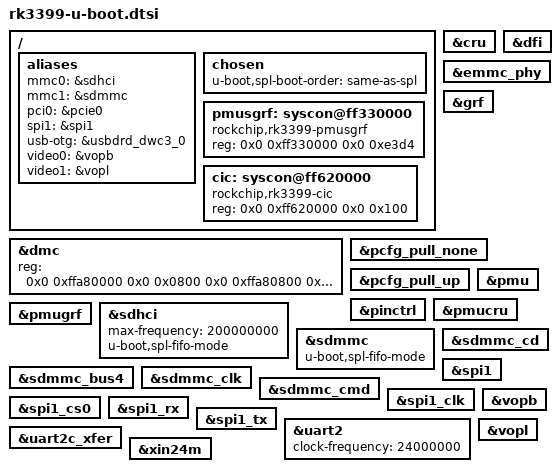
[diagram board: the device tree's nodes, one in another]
// SPDX-License-Identifier: GPL-2.0+
/*
 * Copyright (C) 2019 Jagan Teki <jagan@amarulasolutions.com>
 */
#include "rockchip-u-boot.dtsi"

/ {
	aliases {
		mmc0 = &sdhci;
		mmc1 = &sdmmc;
		pci0 = &pcie0;
		spi1 = &spi1;
		/* the OTG port env usb_otg sets the role of (boot/usb_otg_role.c) */
		usb-otg = &usbdrd_dwc3_0;

		/*
		 * VOPB is video0, VOPL is video1 -- and without these the order
		 * is the reverse, by accident.
		 *
		 * UCLASS_VIDEO carries DM_UC_FLAG_SEQ_ALIAS, so with no videoN
		 * alias the sequence numbers fall out of bind order, which is
		 * device tree node order, and rk3399-base.dtsi happens to list
		 * vop@ff8f0000 (VOPL, 2560x1600) before vop@ff900000 (VOPB,
		 * 4096x2160). That made the small VOP video0.
		 *
		 * It matters because of what probes at boot. With the console
		 * in the environment -- CONFIG_SYS_CONSOLE_IS_IN_ENV, which
		 * CONSOLE_MUX brings in -- stdio_add_devices() skips its
		 * probe-every-video-device loop entirely, and the ONLY boot-path
		 * video probe left is stdio_probe_device() resolving the name
		 * "vidconsole" to UCLASS_VIDEO sequence 0. Exactly one VOP is
		 * probed at boot, and it was the one that cannot drive a 4K
		 * sink.
		 *
		 * That also put it at odds with rk_vop_probe_ranked(), which
		 * reserves the largest sink for the most capable VOP: VOPL,
		 * asked to probe, correctly declined the DisplayPort encoder
		 * held for VOPB and came up idle -- while VOPB, the one that
		 * wanted it, was sequence 1 and never probed. Measured on
		 * roc-rk3399-pc: the Type-C link came up ("PHY up on tcphy1, 4
		 * lanes", "HPD asserted") and no VOP ever drove it.
		 *
		 * SoC-wide rather than per-board because it is a fact about
		 * RK3399 silicon -- VOPB is the big one on every RK3399 -- and
		 * it is the same ranking the driver already encodes.
		 */
		video0 = &vopb;
		video1 = &vopl;
	};

	chosen {
		u-boot,spl-boot-order = "same-as-spl", &sdhci, &sdmmc;
	};

	pmusgrf: syscon@ff330000 {
		compatible = "rockchip,rk3399-pmusgrf", "syscon";
		reg = <0x0 0xff330000 0x0 0xe3d4>;
		bootph-all;
	};

	cic: syscon@ff620000 {
		compatible = "rockchip,rk3399-cic", "syscon";
		reg = <0x0 0xff620000 0x0 0x100>;
		bootph-all;
	};
};

&cru {
	bootph-all;
};

&dfi {
	bootph-all;
};

&dmc {
	reg = <0x0 0xffa80000 0x0 0x0800
	       0x0 0xffa80800 0x0 0x1800
	       0x0 0xffa82000 0x0 0x2000
	       0x0 0xffa84000 0x0 0x1000
	       0x0 0xffa88000 0x0 0x0800
	       0x0 0xffa88800 0x0 0x1800
	       0x0 0xffa8a000 0x0 0x2000
	       0x0 0xffa8c000 0x0 0x1000>;
	bootph-all;
	status = "okay";
};

&emmc_phy {
	bootph-pre-ram;
	bootph-some-ram;
};

&grf {
	bootph-all;
};

&pcfg_pull_none {
	bootph-all;
};

&pcfg_pull_up {
	bootph-all;
};

&pinctrl {
	bootph-all;
};

&pmu {
	bootph-all;
};

&pmucru {
	bootph-all;
};

&pmugrf {
	bootph-all;
};

&sdhci {
	bootph-pre-ram;
	bootph-some-ram;
	max-frequency = <200000000>;

	/* mmc to sram can't do dma, prevent aborts transferring TF-A parts */
	u-boot,spl-fifo-mode;
};

&sdmmc {
	bootph-pre-ram;
	bootph-some-ram;

	/* mmc to sram can't do dma, prevent aborts transferring TF-A parts */
	u-boot,spl-fifo-mode;
};

&sdmmc_bus4 {
	bootph-pre-ram;
	bootph-some-ram;
};

&sdmmc_cd {
	bootph-pre-ram;
	bootph-some-ram;
};

&sdmmc_clk {
	bootph-pre-ram;
	bootph-some-ram;
};

&sdmmc_cmd {
	bootph-pre-ram;
	bootph-some-ram;
};

&spi1 {
	bootph-pre-ram;
	bootph-some-ram;
};

&spi1_clk {
	bootph-pre-ram;
	bootph-some-ram;
};

&spi1_cs0 {
	bootph-pre-ram;
	bootph-some-ram;
};

&spi1_rx {
	bootph-pre-ram;
	bootph-some-ram;
};

&spi1_tx {
	bootph-pre-ram;
	bootph-some-ram;
};

&uart2 {
	bootph-all;
	clock-frequency = <24000000>;
};

&uart2c_xfer {
	bootph-pre-sram;
	bootph-pre-ram;
};

&vopb {
	bootph-some-ram;
};

&vopl {
	bootph-some-ram;
};

&xin24m {
	bootph-all;
};
